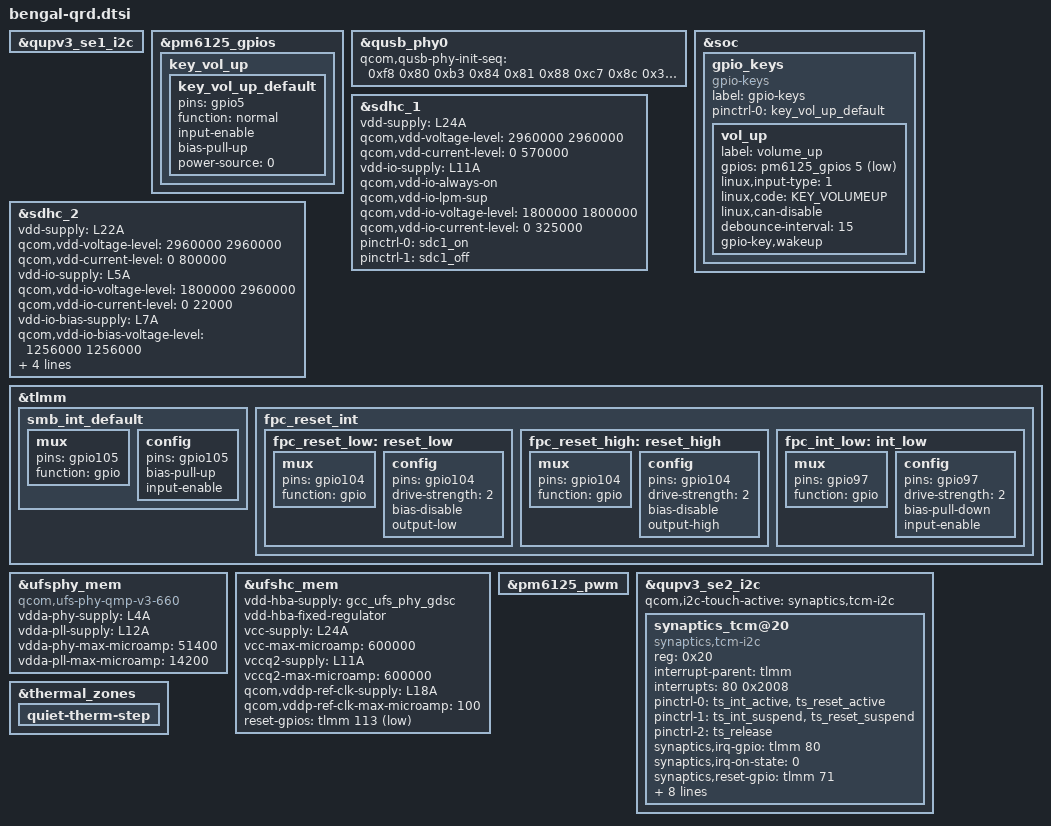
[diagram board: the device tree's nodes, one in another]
#include <dt-bindings/gpio/gpio.h>
#include <dt-bindings/iio/qcom,spmi-vadc.h>
#include <dt-bindings/input/input.h>
#include "bengal-thermal-overlay.dtsi"

&qupv3_se1_i2c {
	status = "ok";
	#include "smb1355.dtsi"
};

&pm6125_gpios {
	key_vol_up {
		key_vol_up_default: key_vol_up_default {
			pins = "gpio5";
			function = "normal";
			input-enable;
			bias-pull-up;
			power-source = <0>;
		};
	};
};

&qusb_phy0 {
	qcom,qusb-phy-init-seq = <0xf8 0x80
				0xb3 0x84
				0x81 0x88
				0xc7 0x8c
				0x30 0x08
				0x79 0x0c
				0x21 0x10
				0x14 0x9c
				0x80 0x04
				0x9f 0x1c
				0x00 0x18>;
};

&soc {
	gpio_keys {
		compatible = "gpio-keys";
		label = "gpio-keys";

		pinctrl-names = "default";
		pinctrl-0 = <&key_vol_up_default>;

		vol_up {
			label = "volume_up";
			gpios = <&pm6125_gpios 5 GPIO_ACTIVE_LOW>;
			linux,input-type = <1>;
			linux,code = <KEY_VOLUMEUP>;
			linux,can-disable;
			debounce-interval = <15>;
			gpio-key,wakeup;
		};
	};
};

&sdhc_1 {
	vdd-supply = <&L24A>;
	qcom,vdd-voltage-level = <2960000 2960000>;
	qcom,vdd-current-level = <0 570000>;

	vdd-io-supply = <&L11A>;
	qcom,vdd-io-always-on;
	qcom,vdd-io-lpm-sup;
	qcom,vdd-io-voltage-level = <1800000 1800000>;
	qcom,vdd-io-current-level = <0 325000>;

	pinctrl-names = "default", "sleep";
	pinctrl-0 = <&sdc1_on>;
	pinctrl-1 = <&sdc1_off>;

	status = "ok";
};

&sdhc_2 {
	vdd-supply = <&L22A>;
	qcom,vdd-voltage-level = <2960000 2960000>;
	qcom,vdd-current-level = <0 800000>;

	vdd-io-supply = <&L5A>;
	qcom,vdd-io-voltage-level = <1800000 2960000>;
	qcom,vdd-io-current-level = <0 22000>;

	vdd-io-bias-supply = <&L7A>;
	qcom,vdd-io-bias-voltage-level = <1256000 1256000>;
	qcom,vdd-io-bias-current-level = <0 6000>;

	pinctrl-names = "default", "sleep";
	pinctrl-0 = <&sdc2_on>;
	pinctrl-1 = <&sdc2_off>;

	cd-gpios = <&tlmm 88 GPIO_ACTIVE_LOW>;

	status = "ok";
};

&tlmm {
	smb_int_default: smb_int_default {
		mux {
			pins = "gpio105";
			function = "gpio";
		};

		config {
			pins = "gpio105";
			bias-pull-up;
			input-enable;
		};
	};
};

&ufsphy_mem {
	compatible = "qcom,ufs-phy-qmp-v3-660";

	vdda-phy-supply = <&L4A>; /* 0.9v */
	vdda-pll-supply = <&L12A>; /* 1.8v */
	vdda-phy-max-microamp = <51400>;
	vdda-pll-max-microamp = <14200>;

	status = "ok";
};

&ufshc_mem {
	vdd-hba-supply = <&gcc_ufs_phy_gdsc>;
	vdd-hba-fixed-regulator;

	vcc-supply = <&L24A>;
	vcc-max-microamp = <600000>;

	vccq2-supply = <&L11A>;
	vccq2-max-microamp = <600000>;

	qcom,vddp-ref-clk-supply = <&L18A>;
	qcom,vddp-ref-clk-max-microamp = <100>;

	reset-gpios = <&tlmm 113 GPIO_ACTIVE_LOW>;
	reset-names = "rst";

	status = "ok";
};

&pm6125_pwm {
	status = "ok";
};

&qupv3_se2_i2c {
	status = "okay";
	qcom,i2c-touch-active="synaptics,tcm-i2c";

	synaptics_tcm@20 {
		compatible = "synaptics,tcm-i2c";
		reg = <0x20>;
		interrupt-parent = <&tlmm>;
		interrupts = <80 0x2008>;
		pinctrl-names = "pmx_ts_active","pmx_ts_suspend",
			"pmx_ts_release";
		pinctrl-0 = <&ts_int_active &ts_reset_active>;
		pinctrl-1 = <&ts_int_suspend &ts_reset_suspend>;
		pinctrl-2 = <&ts_release>;
		synaptics,irq-gpio = <&tlmm 80 0x2008>;
		synaptics,irq-on-state = <0>;
		synaptics,reset-gpio = <&tlmm 71 0x00>;
		synaptics,reset-on-state = <0>;
		synaptics,reset-active-ms = <20>;
		synaptics,reset-delay-ms = <200>;
		synaptics,power-delay-ms = <200>;
		synaptics,ubl-i2c-addr = <0x20>;
		synaptics,extend_report;
		synaptics,firmware-name = "synaptics_firmware_k.img";

	};
};

&thermal_zones {
	quiet-therm-step {
		status = "ok";
	};
};

&tlmm {
	fpc_reset_int: fpc_reset_int {
		fpc_reset_low: reset_low {
			mux {
				pins = "gpio104";
				function = "gpio";
			};

			config {
				pins = "gpio104";
				drive-strength = <2>;
				bias-disable;
				output-low;
			};
		};

		fpc_reset_high: reset_high {
			mux {
				pins = "gpio104";
				function = "gpio";
			};

			config {
				pins = "gpio104";
				drive-strength = <2>;
				bias-disable;
				output-high;
			};
		};

		fpc_int_low: int_low {
			mux {
				pins = "gpio97";
				function = "gpio";
			};

			config {
				pins = "gpio97";
				drive-strength = <2>;
				bias-pull-down;
				input-enable;
			};
		};
	};
};
